VERSION ""

NS_ :

BS_:

BU_: DRIVER MOTOR SENSOR GPS BRIDGE

BO_ 100 APP_START_STOP: 1 BRIDGE
 SG_ BRIDGE_START : 0|1@1+ (1,0) [0|0] "" DRIVER

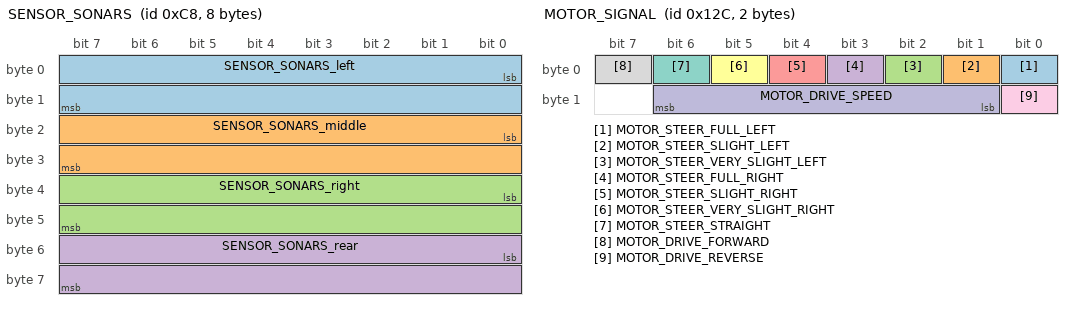
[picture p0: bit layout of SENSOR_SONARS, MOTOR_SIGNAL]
BO_ 200 SENSOR_SONARS: 8 SENSOR
 SG_ SENSOR_SONARS_left : 0|16@1+ (1,0) [0|256] "inches" DRIVER,IO
 SG_ SENSOR_SONARS_middle : 16|16@1+ (1,0) [0|256] "inches" DRIVER,IO
 SG_ SENSOR_SONARS_right : 32|16@1+ (1,0) [0|256] "inches" DRIVER,IO
 SG_ SENSOR_SONARS_rear : 48|16@1+ (1,0) [0|256] "inches" DRIVER,IO

BO_ 300 MOTOR_SIGNAL: 2 DRIVER
 SG_ MOTOR_STEER_FULL_LEFT : 0|1@1+ (1,0) [0|0] "" MOTOR
 SG_ MOTOR_STEER_SLIGHT_LEFT : 1|1@1+ (1,0) [0|0] "" MOTOR
 SG_ MOTOR_STEER_VERY_SLIGHT_LEFT : 2|1@1+ (1,0) [0|0] "" MOTOR
 SG_ MOTOR_STEER_FULL_RIGHT : 3|1@1+ (1,0) [0|0] "" MOTOR
 SG_ MOTOR_STEER_SLIGHT_RIGHT : 4|1@1+ (1,0) [0|0] "" MOTOR
 SG_ MOTOR_STEER_VERY_SLIGHT_RIGHT : 5|1@1+ (1,0) [0|0] "" MOTOR
 SG_ MOTOR_STEER_STRAIGHT : 6|1@1+ (1,0) [0|0] "" MOTOR
 SG_ MOTOR_DRIVE_FORWARD : 7|1@1+ (1,0) [0|0] "" MOTOR
 SG_ MOTOR_DRIVE_REVERSE : 8|1@1+ (1,0) [0|0] "" MOTOR
 SG_ MOTOR_DRIVE_SPEED : 9|6@1+ (0.1,0) [0.0|6.0] "mph" MOTOR

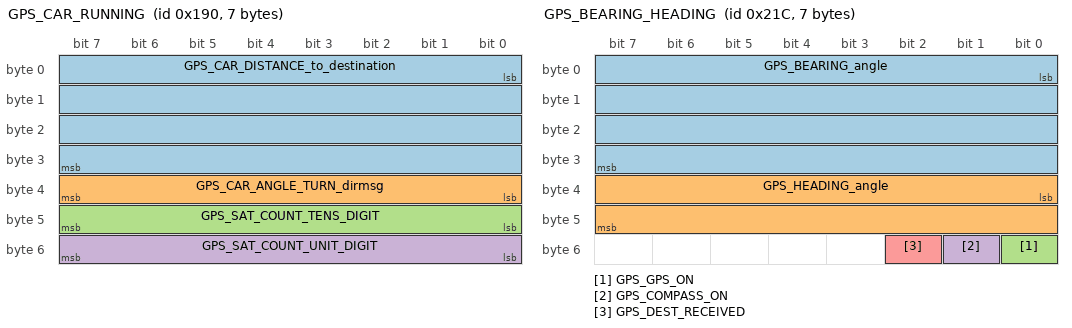
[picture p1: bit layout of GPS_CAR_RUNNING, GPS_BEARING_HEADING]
BO_ 400 GPS_CAR_RUNNING: 7 GPS
 SG_ GPS_CAR_DISTANCE_to_destination : 0|32@1+ (1,0) [0|0] "" BRIDGE,DRIVER
 SG_ GPS_CAR_ANGLE_TURN_dirmsg : 32|8@1+ (1,0) [0|0] "" BRIDGE,DRIVER
 SG_ GPS_SAT_COUNT_TENS_DIGIT : 40|8@1+ (1,0) [0|0] "" BRIDGE,DRIVER
 SG_ GPS_SAT_COUNT_UNIT_DIGIT : 48|8@1+ (1,0) [0|0] "" BRIDGE,DRIVER

BO_ 500 GPS_CHECKPOINT_DESTINATION: 8 BRIDGE
 SG_ GPS_latitude : 0|32@1+ (1,0) [0|0] "" GPS
 SG_ GPS_longitude : 32|32@1+ (1,0) [0|0] "" GPS

BO_ 540 GPS_BEARING_HEADING: 7  GPS
 SG_ GPS_BEARING_angle : 0|32@1+ (1,0) [0|0] "" BRIDGE
 SG_ GPS_HEADING_angle : 32|16@1+ (1,0) [0|0] "" BRIDGE
 SG_ GPS_GPS_ON : 48|1@1+ (1,0) [0|0] "" BRIDGE
 SG_ GPS_COMPASS_ON : 49|1@1+ (1,0) [0|0] "" BRIDGE
 SG_ GPS_DEST_RECEIVED : 50|1@1+ (1,0) [0|0] "" BRIDGE

BO_ 555 GPS_CURRENT_LOCATION: 8 GPS
 SG_ GPS_CURRENT_LOCATION_latitude : 0|32@1+ (1,0) [0|0] "" BRIDGE
 SG_ GPS_CURRENT_LOCATION_longitude : 32|32@1+ (1,0) [0|0] "" BRIDGE

BO_ 688 SPEED_RPM: 4 MOTOR
 SG_ SPEED_RPM_float : 0|10@1+ (0.01,10.00) [10.00|20.00] "" BRIDGE

BO_ 695 HEARTBEAT_GPS: 1 GPS
 SG_ GPS_CONNECTED : 0|1@1+ (1,0) [0|0] "" DRIVER

BO_ 700 HEARTBEAT_BRIDGE: 1 BRIDGE
 SG_ BRIDGE_CONNECTED : 0|1@1+ (1,0) [0|0] "" DRIVER
